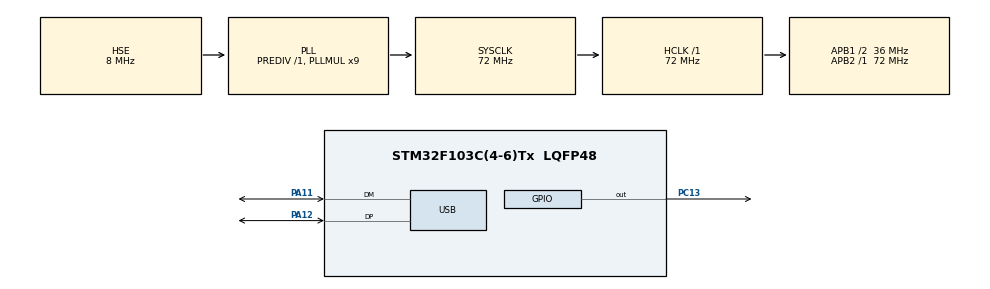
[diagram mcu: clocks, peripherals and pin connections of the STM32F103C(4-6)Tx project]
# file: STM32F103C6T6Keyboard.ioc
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Mcu.Family=STM32F1
Mcu.Name=STM32F103C(4-6)Tx
Mcu.Package=LQFP48
NVIC.PriorityGroup=NVIC_PRIORITYGROUP_4
NVIC.USB_LP_CAN1_RX0_IRQn=true\:0\:0\:false\:false\:true\:false\:true\:true
PA11.Mode=Device
PA11.Signal=USB_DM
PA12.Mode=Device
PA12.Signal=USB_DP
PA13.Mode=Serial_Wire
PA13.Signal=SYS_JTMS-SWDIO
PA14.Mode=Serial_Wire
PA14.Signal=SYS_JTCK-SWCLK
PC13-TAMPER-RTC.Signal=GPIO_Output
PC14-OSC32_IN.Mode=LSE-External-Oscillator
PC14-OSC32_IN.Signal=RCC_OSC32_IN
PC15-OSC32_OUT.Mode=LSE-External-Oscillator
PC15-OSC32_OUT.Signal=RCC_OSC32_OUT
PD0-OSC_IN.Mode=HSE-External-Oscillator
PD0-OSC_IN.Signal=RCC_OSC_IN
PD1-OSC_OUT.Mode=HSE-External-Oscillator
PD1-OSC_OUT.Signal=RCC_OSC_OUT
ProjectManager.HeapSize=0x200
ProjectManager.StackSize=0x400
ProjectManager.TargetToolchain=Makefile
RCC.AHBFreq_Value=72000000
RCC.APB1CLKDivider=RCC_HCLK_DIV2
RCC.APB1Freq_Value=36000000
RCC.APB1TimFreq_Value=72000000
RCC.APB2Freq_Value=72000000
RCC.APB2TimFreq_Value=72000000
RCC.HCLKFreq_Value=72000000
RCC.PLLMUL=RCC_PLL_MUL9
RCC.SYSCLKFreq_VALUE=72000000
RCC.SYSCLKSource=RCC_SYSCLKSOURCE_PLLCLK
RCC.USBFreq_Value=48000000
RCC.USBPrescaler=RCC_USBCLKSOURCE_PLL_DIV1_5
USB_DEVICE.CLASS_NAME_FS=CUSTOM_HID
USB_DEVICE.CUSTOM_HID_FS_BINTERVAL=1
USB_DEVICE.MANUFACTURER_STRING=AKB Co.
USB_DEVICE.PRODUCT_STRING_CUSTOMHID_FS=AKB - USB Keyboard
USB_DEVICE.USBD_CUSTOM_HID_REPORT_DESC_SIZE=63
USB_DEVICE.VirtualMode=CustomHid
USB_DEVICE.VirtualModeFS=Custom_Hid_FS
VP_USB_DEVICE_VS_USB_DEVICE_CUSTOM_HID_FS.Mode=CUSTOM_HID_FS
board=custom

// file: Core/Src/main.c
/* USER CODE BEGIN Header */
/**
  ******************************************************************************
  * @file           : main.c
  * @brief          : Main program body
  ******************************************************************************
  * @attention
  *
  * Copyright (c) 2026 STMicroelectronics.
  * All rights reserved.
  *
  * This software is licensed under terms that can be found in the LICENSE file
  * in the root directory of this software component.
  * If no LICENSE file comes with this software, it is provided AS-IS.
  *
  ******************************************************************************
  */
/* USER CODE END Header */
#include "main.h"
#include "usb_device.h"

/* USER CODE BEGIN Includes */
#include "usbd_hid.h"
#include "usbd_customhid.h"

/* USER CODE END Includes */

/* USER CODE BEGIN PV */
extern USBD_HandleTypeDef hUsbDeviceFS;

typedef struct {
    uint8_t MODIFIER;
    uint8_t RESERVED;
    uint8_t KEYCODE1;
    uint8_t KEYCODE2;
    uint8_t KEYCODE3;
    uint8_t KEYCODE4;
    uint8_t KEYCODE5;
    uint8_t KEYCODE6;
} KeyboardReport;

KeyboardReport keyboard_report = {0};

void Keyboard_SendKey(uint8_t modifier, uint8_t keycode) {
    if (hUsbDeviceFS.pClassData == NULL) return;
    if (hUsbDeviceFS.dev_state != USBD_STATE_CONFIGURED) return;

    USBD_CUSTOM_HID_HandleTypeDef* hhid =
        (USBD_CUSTOM_HID_HandleTypeDef*)hUsbDeviceFS.pClassData;

    // Hazır olana kadar bekle
    uint32_t timeout = HAL_GetTick() + 200;
    while (hhid->state != CUSTOM_HID_IDLE) {
        if (HAL_GetTick() > timeout) return;
        HAL_Delay(1);
    }

    // Tuşa bas
    keyboard_report.MODIFIER = modifier;
    keyboard_report.KEYCODE1 = keycode;
    USBD_CUSTOM_HID_SendReport(&hUsbDeviceFS,
                               (uint8_t*)&keyboard_report,
                               sizeof(keyboard_report));
    HAL_Delay(30);

    // Tuşu bırak
    keyboard_report.MODIFIER = 0;
    keyboard_report.KEYCODE1 = 0;

    timeout = HAL_GetTick() + 200;
    while (hhid->state != CUSTOM_HID_IDLE) {
        if (HAL_GetTick() > timeout) return;
        HAL_Delay(1);
    }

    USBD_CUSTOM_HID_SendReport(&hUsbDeviceFS,
                               (uint8_t*)&keyboard_report,
                               sizeof(keyboard_report));
    HAL_Delay(30);
}

/* USER CODE END PV */

void SystemClock_Config(void);
static void MX_GPIO_Init(void);

int main(void) {

    /* MCU Configuration--------------------------------------------------------*/

    /* Reset of all peripherals, Initializes the Flash interface and the Systick. */
    HAL_Init();

    /* Configure the system clock */
    SystemClock_Config();

    /* Initialize all configured peripherals */
    MX_GPIO_Init();
    MX_USB_DEVICE_Init();
    /* USER CODE BEGIN 2 */

    Keyboard_SendKey(0x00, 0xE1); // Left-Shift
    HAL_Delay(100); // Uyanma süresi
    Keyboard_SendKey(0x00, 0xE1);
    HAL_Delay(100);
    Keyboard_SendKey(0x00, 0xE1);
    HAL_Delay(100);
    Keyboard_SendKey(0x00, 0xE1);
    HAL_Delay(100);
    Keyboard_SendKey(0x00, 0xE1);
    HAL_Delay(200);

    HAL_GPIO_WritePin(GPIOC, GPIO_PIN_13, GPIO_PIN_RESET);

    Keyboard_SendKey(0x00, 0x1E); // '1'
    HAL_Delay(100);
    Keyboard_SendKey(0x00, 0x21); // '4'
    HAL_Delay(100);
    Keyboard_SendKey(0x00, 0x22); // '5'
    HAL_Delay(100);
    Keyboard_SendKey(0x00, 0x20); // '3'
    HAL_Delay(100);
    Keyboard_SendKey(0x00, 0x28); // 'Enter'
    HAL_Delay(100);

    // Stop USB
    //USBD_Stop(&hUsbDeviceFS);
    //USBD_DeInit(&hUsbDeviceFS);

    HAL_GPIO_WritePin(GPIOC, GPIO_PIN_13, GPIO_PIN_SET);

    // Power Saving Mode
    // HAL_PWR_EnterSTOPMode(PWR_MAINREGULATOR_ON, PWR_STOPENTRY_WFI);

    /* USER CODE END 2 */

    /* Infinite loop */
    while (1) {

    }
}

void SystemClock_Config(void) {
    RCC_OscInitTypeDef RCC_OscInitStruct = {0};
    RCC_ClkInitTypeDef RCC_ClkInitStruct = {0};
    RCC_PeriphCLKInitTypeDef PeriphClkInit = {0};

    /** Initializes the RCC Oscillators according to the specified parameters
    * in the RCC_OscInitTypeDef structure.
    */
    RCC_OscInitStruct.OscillatorType = RCC_OSCILLATORTYPE_HSE;
    RCC_OscInitStruct.HSEState = RCC_HSE_ON;
    RCC_OscInitStruct.HSEPredivValue = RCC_HSE_PREDIV_DIV1;
    RCC_OscInitStruct.HSIState = RCC_HSI_ON;
    RCC_OscInitStruct.PLL.PLLState = RCC_PLL_ON;
    RCC_OscInitStruct.PLL.PLLSource = RCC_PLLSOURCE_HSE;
    RCC_OscInitStruct.PLL.PLLMUL = RCC_PLL_MUL9;
    if (HAL_RCC_OscConfig(&RCC_OscInitStruct) != HAL_OK) {
        Error_Handler();
    }

    /** Initializes the CPU, AHB and APB buses clocks
    */
    RCC_ClkInitStruct.ClockType = RCC_CLOCKTYPE_HCLK | RCC_CLOCKTYPE_SYSCLK
        | RCC_CLOCKTYPE_PCLK1 | RCC_CLOCKTYPE_PCLK2;
    RCC_ClkInitStruct.SYSCLKSource = RCC_SYSCLKSOURCE_PLLCLK;
    RCC_ClkInitStruct.AHBCLKDivider = RCC_SYSCLK_DIV1;
    RCC_ClkInitStruct.APB1CLKDivider = RCC_HCLK_DIV2;
    RCC_ClkInitStruct.APB2CLKDivider = RCC_HCLK_DIV1;

    if (HAL_RCC_ClockConfig(&RCC_ClkInitStruct, FLASH_LATENCY_2) != HAL_OK) {
        Error_Handler();
    }
    PeriphClkInit.PeriphClockSelection = RCC_PERIPHCLK_USB;
    PeriphClkInit.UsbClockSelection = RCC_USBCLKSOURCE_PLL_DIV1_5;
    if (HAL_RCCEx_PeriphCLKConfig(&PeriphClkInit) != HAL_OK) {
        Error_Handler();
    }
}

static void MX_GPIO_Init(void) {
    GPIO_InitTypeDef GPIO_InitStruct = {0};

    /* GPIO Ports Clock Enable */
    __HAL_RCC_GPIOC_CLK_ENABLE();
    __HAL_RCC_GPIOD_CLK_ENABLE();
    __HAL_RCC_GPIOA_CLK_ENABLE();

    /*Configure GPIO pin Output Level */
    HAL_GPIO_WritePin(GPIOC, GPIO_PIN_13, GPIO_PIN_RESET);

    /*Configure GPIO pin : PC13 */
    GPIO_InitStruct.Pin = GPIO_PIN_13;
    GPIO_InitStruct.Mode = GPIO_MODE_OUTPUT_PP;
    GPIO_InitStruct.Pull = GPIO_NOPULL;
    GPIO_InitStruct.Speed = GPIO_SPEED_FREQ_LOW;
    HAL_GPIO_Init(GPIOC, &GPIO_InitStruct);

}

void Error_Handler(void) {
    __disable_irq();
    while (1) {
    }
}
